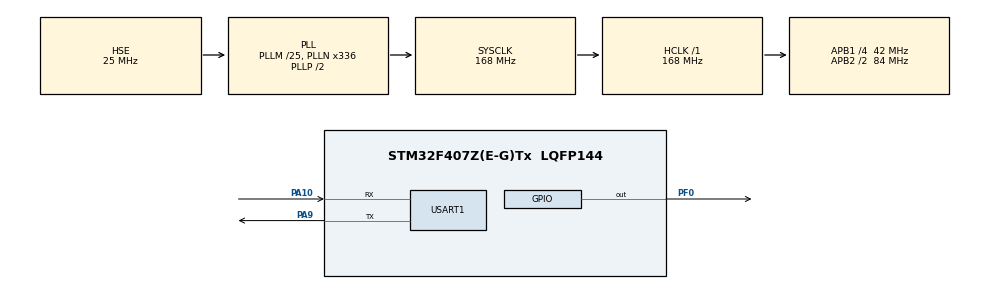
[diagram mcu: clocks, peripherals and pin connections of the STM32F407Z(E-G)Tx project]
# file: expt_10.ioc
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Dma.Request0=USART1_RX
Dma.Request1=USART1_TX
Dma.USART1_RX.0.Direction=DMA_PERIPH_TO_MEMORY
Dma.USART1_RX.0.FIFOMode=DMA_FIFOMODE_DISABLE
Dma.USART1_RX.0.Instance=DMA2_Stream2
Dma.USART1_RX.0.MemDataAlignment=DMA_MDATAALIGN_BYTE
Dma.USART1_RX.0.MemInc=DMA_MINC_ENABLE
Dma.USART1_RX.0.Mode=DMA_NORMAL
Dma.USART1_RX.0.PeriphDataAlignment=DMA_PDATAALIGN_BYTE
Dma.USART1_RX.0.PeriphInc=DMA_PINC_DISABLE
Dma.USART1_RX.0.Priority=DMA_PRIORITY_LOW
Dma.USART1_TX.1.Direction=DMA_MEMORY_TO_PERIPH
Dma.USART1_TX.1.FIFOMode=DMA_FIFOMODE_DISABLE
Dma.USART1_TX.1.Instance=DMA2_Stream7
Dma.USART1_TX.1.MemDataAlignment=DMA_MDATAALIGN_BYTE
Dma.USART1_TX.1.MemInc=DMA_MINC_ENABLE
Dma.USART1_TX.1.Mode=DMA_NORMAL
Dma.USART1_TX.1.PeriphDataAlignment=DMA_PDATAALIGN_BYTE
Dma.USART1_TX.1.PeriphInc=DMA_PINC_DISABLE
Dma.USART1_TX.1.Priority=DMA_PRIORITY_LOW
FREERTOS.Tasks01=defaultTask,24,128,StartDefaultTask,Default,NULL,Dynamic,NULL,NULL;myTask02,8,128,StartTask02,Default,NULL,Dynamic,NULL,NULL
Mcu.Family=STM32F4
Mcu.Name=STM32F407Z(E-G)Tx
Mcu.Package=LQFP144
NVIC.DMA2_Stream2_IRQn=true\:5\:0\:false\:false\:true\:true\:false\:true\:true
NVIC.DMA2_Stream7_IRQn=true\:5\:0\:false\:false\:true\:true\:false\:true\:true
NVIC.PriorityGroup=NVIC_PRIORITYGROUP_4
NVIC.TIM8_TRG_COM_TIM14_IRQn=true\:15\:0\:false\:false\:true\:false\:false\:true\:true
NVIC.TimeBase=TIM8_TRG_COM_TIM14_IRQn
NVIC.TimeBaseIP=TIM14
NVIC.USART1_IRQn=true\:5\:0\:false\:false\:true\:true\:true\:true\:true
PA10.Mode=Asynchronous
PA10.Signal=USART1_RX
PA13.Mode=Serial_Wire
PA13.Signal=SYS_JTMS-SWDIO
PA14.Mode=Serial_Wire
PA14.Signal=SYS_JTCK-SWCLK
PA9.Mode=Asynchronous
PA9.Signal=USART1_TX
PF0.PinState=GPIO_PIN_SET
PF0.Signal=GPIO_Output
PH0-OSC_IN.Mode=HSE-External-Oscillator
PH0-OSC_IN.Signal=RCC_OSC_IN
PH1-OSC_OUT.Mode=HSE-External-Oscillator
PH1-OSC_OUT.Signal=RCC_OSC_OUT
ProjectManager.HeapSize=0x200
ProjectManager.StackSize=0x400
ProjectManager.TargetToolchain=MDK-ARM V5.32
RCC.48MHZClocksFreq_Value=84000000
RCC.AHBFreq_Value=168000000
RCC.APB1CLKDivider=RCC_HCLK_DIV4
RCC.APB1Freq_Value=42000000
RCC.APB1TimFreq_Value=84000000
RCC.APB2CLKDivider=RCC_HCLK_DIV2
RCC.APB2Freq_Value=84000000
RCC.APB2TimFreq_Value=168000000
RCC.CortexFreq_Value=168000000
RCC.HCLKFreq_Value=168000000
RCC.HSE_VALUE=25000000
RCC.HSI_VALUE=16000000
RCC.LSE_VALUE=32768
RCC.PLLM=25
RCC.PLLN=336
RCC.PLLSourceVirtual=RCC_PLLSOURCE_HSE
RCC.SYSCLKFreq_VALUE=168000000
RCC.SYSCLKSource=RCC_SYSCLKSOURCE_PLLCLK
RCC.VCOOutputFreq_Value=336000000
USART1.VirtualMode=VM_ASYNC
VP_FREERTOS_VS_CMSIS_V2.Mode=CMSIS_V2
VP_SYS_VS_tim14.Mode=TIM14
board=custom

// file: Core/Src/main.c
/* USER CODE BEGIN Header */
/**
 ******************************************************************************
 * @file           : main.c
 * @brief          : Main program body
 ******************************************************************************
 * @attention
 *
 * Copyright (c) 2022 STMicroelectronics.
 * All rights reserved.
 *
 * This software is licensed under terms that can be found in the LICENSE file
 * in the root directory of this software component.
 * If no LICENSE file comes with this software, it is provided AS-IS.
 *
 ******************************************************************************
 */
/* USER CODE END Header */
#include "main.h"

#include "cmsis_os.h"
#include "dma.h"
#include "gpio.h"
#include "usart.h"

/* USER CODE BEGIN Includes */
#include <stdio.h>
/* USER CODE END Includes */

/* USER CODE BEGIN PV */
const uint16_t buffer_size = 10;
char send_buffer[buffer_size] = "1";
char recv_buffer[buffer_size];
/* USER CODE END PV */

void SystemClock_Config(void);
void MX_FREERTOS_Init(void);

int main(void) {

    /* MCU Configuration--------------------------------------------------------*/

    /* Reset of all peripherals, Initializes the Flash interface and the Systick. */
    HAL_Init();

    /* Configure the system clock */
    SystemClock_Config();

    /* Initialize all configured peripherals */
    MX_GPIO_Init();
    MX_DMA_Init();
    MX_USART1_UART_Init();
    /* USER CODE BEGIN 2 */
    //	HAL_DMA_DeInit(huart1.hdmatx);
    //	HAL_DMA_Init(huart1.hdmatx);
    sprintf(send_buffer, "%s", send_buffer);
    HAL_UART_Transmit_DMA(&huart1, (uint8_t *)send_buffer, sizeof(buffer_size));
    HAL_UART_Receive_IT(&huart1, (uint8_t *)recv_buffer, sizeof(recv_buffer));
    /* USER CODE END 2 */

    /* Init scheduler */
    osKernelInitialize(); /* Call init function for freertos objects (in freertos.c) */
    MX_FREERTOS_Init();

    /* Start scheduler */
    osKernelStart();

    /* We should never get here as control is now taken by the scheduler */
    /* Infinite loop */
    while (1) {

        /* USER CODE BEGIN 3 */
        HAL_GPIO_WritePin(GPIOF, GPIO_PIN_0, GPIO_PIN_RESET);
        HAL_Delay(500);
        HAL_GPIO_WritePin(GPIOF, GPIO_PIN_0, GPIO_PIN_SET);
        HAL_Delay(500);
    }
    /* USER CODE END 3 */
}

void SystemClock_Config(void) {
    RCC_OscInitTypeDef RCC_OscInitStruct = {0};
    RCC_ClkInitTypeDef RCC_ClkInitStruct = {0};

    /** Configure the main internal regulator output voltage
     */
    __HAL_RCC_PWR_CLK_ENABLE();
    __HAL_PWR_VOLTAGESCALING_CONFIG(PWR_REGULATOR_VOLTAGE_SCALE1);

    /** Initializes the RCC Oscillators according to the specified parameters
     * in the RCC_OscInitTypeDef structure.
     */
    RCC_OscInitStruct.OscillatorType = RCC_OSCILLATORTYPE_HSE;
    RCC_OscInitStruct.HSEState = RCC_HSE_ON;
    RCC_OscInitStruct.PLL.PLLState = RCC_PLL_ON;
    RCC_OscInitStruct.PLL.PLLSource = RCC_PLLSOURCE_HSE;
    RCC_OscInitStruct.PLL.PLLM = 25;
    RCC_OscInitStruct.PLL.PLLN = 336;
    RCC_OscInitStruct.PLL.PLLP = RCC_PLLP_DIV2;
    RCC_OscInitStruct.PLL.PLLQ = 4;
    if (HAL_RCC_OscConfig(&RCC_OscInitStruct) != HAL_OK) {
        Error_Handler();
    }

    /** Initializes the CPU, AHB and APB buses clocks
     */
    RCC_ClkInitStruct.ClockType = RCC_CLOCKTYPE_HCLK | RCC_CLOCKTYPE_SYSCLK | RCC_CLOCKTYPE_PCLK1 | RCC_CLOCKTYPE_PCLK2;
    RCC_ClkInitStruct.SYSCLKSource = RCC_SYSCLKSOURCE_PLLCLK;
    RCC_ClkInitStruct.AHBCLKDivider = RCC_SYSCLK_DIV1;
    RCC_ClkInitStruct.APB1CLKDivider = RCC_HCLK_DIV4;
    RCC_ClkInitStruct.APB2CLKDivider = RCC_HCLK_DIV2;

    if (HAL_RCC_ClockConfig(&RCC_ClkInitStruct, FLASH_LATENCY_5) != HAL_OK) {
        Error_Handler();
    }
}

/* USER CODE BEGIN 4 */
void HAL_UART_RxCpltCallback(UART_HandleTypeDef *huart) {
    HAL_UART_Transmit_DMA(&huart1, (uint8_t *)send_buffer, sizeof(send_buffer));
    HAL_UART_Receive_IT(&huart1, (uint8_t *)recv_buffer, sizeof(recv_buffer));
}
/* USER CODE END 4 */

void HAL_TIM_PeriodElapsedCallback(TIM_HandleTypeDef *htim) {
    if (htim->Instance == TIM14) {
        HAL_IncTick();
    }
}

void Error_Handler(void) {
    __disable_irq();
    while (1) {
    }
}

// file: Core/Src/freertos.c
/* USER CODE BEGIN Header */
/**
  ******************************************************************************
  * File Name          : freertos.c
  * Description        : Code for freertos applications
  ******************************************************************************
  * @attention
  *
  * Copyright (c) 2022 STMicroelectronics.
  * All rights reserved.
  *
  * This software is licensed under terms that can be found in the LICENSE file
  * in the root directory of this software component.
  * If no LICENSE file comes with this software, it is provided AS-IS.
  *
  ******************************************************************************
  */
/* USER CODE END Header */

#include "FreeRTOS.h"
#include "task.h"
#include "main.h"
#include "cmsis_os.h"

/* USER CODE BEGIN Includes */
#include "usart.h"
/* USER CODE END Includes */

/* USER CODE BEGIN Variables */
extern char send_buffer[10];
/* USER CODE END Variables */
/* Definitions for defaultTask */
osThreadId_t defaultTaskHandle;
const osThreadAttr_t defaultTask_attributes = {
  .name = "defaultTask",
  .stack_size = 128 * 4,
  .priority = (osPriority_t) osPriorityNormal,
};
/* Definitions for myTask02 */
osThreadId_t myTask02Handle;
const osThreadAttr_t myTask02_attributes = {
  .name = "myTask02",
  .stack_size = 128 * 4,
  .priority = (osPriority_t) osPriorityLow,
};

void StartDefaultTask(void *argument);
void StartTask02(void *argument);

void MX_FREERTOS_Init(void); /* (MISRA C 2004 rule 8.1) */

void MX_FREERTOS_Init(void) {

  /* Create the thread(s) */
  /* creation of defaultTask */
  defaultTaskHandle = osThreadNew(StartDefaultTask, NULL, &defaultTask_attributes);

  /* creation of myTask02 */
  myTask02Handle = osThreadNew(StartTask02, NULL, &myTask02_attributes);

}

void StartDefaultTask(void *argument)
{
  /* USER CODE BEGIN StartDefaultTask */
  /* Infinite loop */
  for(;;)
  {
    HAL_GPIO_WritePin(GPIOF, GPIO_PIN_0, GPIO_PIN_RESET);
		osDelay(500);
		HAL_GPIO_WritePin(GPIOF, GPIO_PIN_0, GPIO_PIN_SET);
		osDelay(500);
  }
  /* USER CODE END StartDefaultTask */
}

void StartTask02(void *argument)
{
  /* USER CODE BEGIN StartTask02 */
  /* Infinite loop */
  for(;;)
  {
		HAL_UART_Transmit_DMA(&huart1, (uint8_t*)send_buffer, sizeof(send_buffer));
    osDelay(1);
  }
  /* USER CODE END StartTask02 */
}
